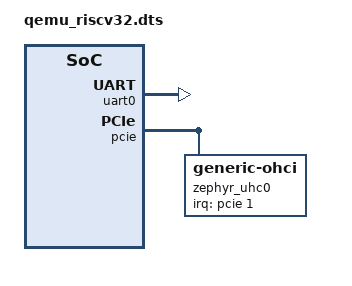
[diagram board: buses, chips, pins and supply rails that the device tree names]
/* SPDX-License-Identifier: Apache-2.0 */

/dts-v1/;

#include <qemu/virt-riscv32.dtsi>

/ {
	chosen {
		zephyr,console = &uart0;
		zephyr,shell-uart = &uart0;
		zephyr,sram = &ram0;
	};
};

&uart0 {
	status = "okay";
};

&pcie {
	zephyr_uhc0: pcie@2,0 {
		compatible = "generic-ohci";
		reg = <0x1000 0 0 0 0>;
		vendor-id = <0x106b>;
		device-id = <0x003f>;
		interrupts = <1>;
		interrupt-parent = <&pcie>;
		maximum-speed = "full-speed";
		dma-coherent;
		status = "okay";
	};
};
